VERSION "created by canmatrix"

NS_ :

BS_ :

BU_:

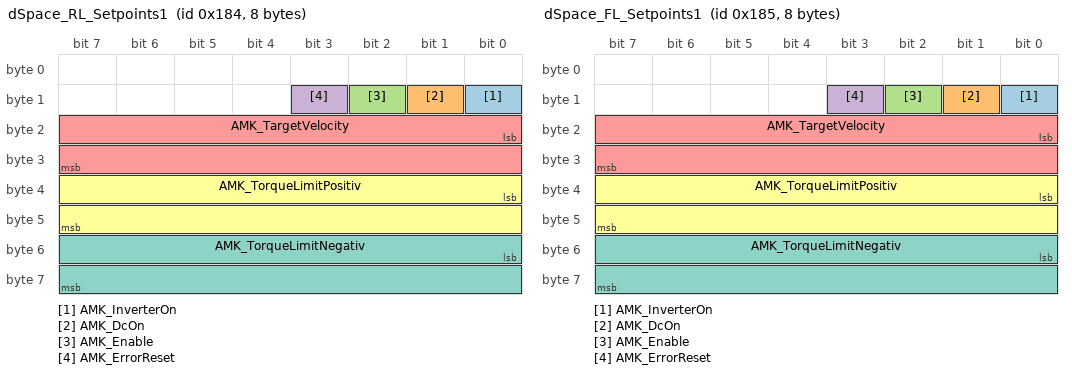
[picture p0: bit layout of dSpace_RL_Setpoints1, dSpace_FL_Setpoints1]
BO_ 388 dSpace_RL_Setpoints1: 8 Vector__XXX
  SG_ AMK_InverterOn : 8|1@1- (1,0) [0|1] "" Vector__XXX
  SG_ AMK_DcOn : 9|1@1- (1,0) [0|1] "" Vector__XXX
  SG_ AMK_Enable : 10|1@1- (1,0) [0|1] "" Vector__XXX
  SG_ AMK_ErrorReset : 11|1@1- (1,0) [0|1] "" Vector__XXX
  SG_ AMK_TargetVelocity : 16|16@1- (1,0) [-32768|32767] "" Vector__XXX
  SG_ AMK_TorqueLimitPositiv : 32|16@1- (1,0) [-32768|32767] "" Vector__XXX
  SG_ AMK_TorqueLimitNegativ : 48|16@1- (1,0) [-32768|32767] "" Vector__XXX

BO_ 389 dSpace_FL_Setpoints1: 8 Vector__XXX
  SG_ AMK_InverterOn : 8|1@1- (1,0) [0|1] "" Vector__XXX
  SG_ AMK_DcOn : 9|1@1- (1,0) [0|1] "" Vector__XXX
  SG_ AMK_Enable : 10|1@1- (1,0) [0|1] "" Vector__XXX
  SG_ AMK_ErrorReset : 11|1@1- (1,0) [0|1] "" Vector__XXX
  SG_ AMK_TargetVelocity : 16|16@1- (1,0) [-32768|32767] "" Vector__XXX
  SG_ AMK_TorqueLimitPositiv : 32|16@1- (1,0) [-32768|32767] "" Vector__XXX
  SG_ AMK_TorqueLimitNegativ : 48|16@1- (1,0) [-32768|32767] "" Vector__XXX

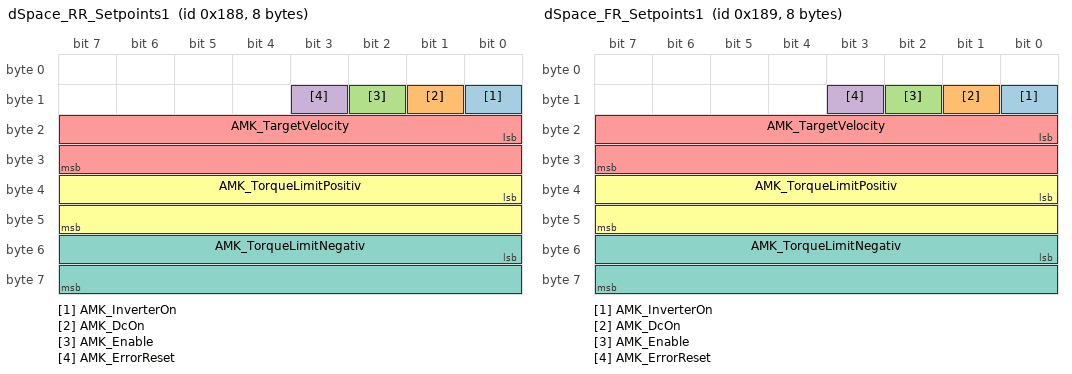
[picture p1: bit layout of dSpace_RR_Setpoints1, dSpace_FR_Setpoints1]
BO_ 392 dSpace_RR_Setpoints1: 8 Vector__XXX
  SG_ AMK_InverterOn : 8|1@1- (1,0) [0|1] "" Vector__XXX
  SG_ AMK_DcOn : 9|1@1- (1,0) [0|1] "" Vector__XXX
  SG_ AMK_Enable : 10|1@1- (1,0) [0|1] "" Vector__XXX
  SG_ AMK_ErrorReset : 11|1@1- (1,0) [0|1] "" Vector__XXX
  SG_ AMK_TargetVelocity : 16|16@1- (1,0) [-32768|32767] "" Vector__XXX
  SG_ AMK_TorqueLimitPositiv : 32|16@1- (1,0) [-32768|32767] "" Vector__XXX
  SG_ AMK_TorqueLimitNegativ : 48|16@1- (1,0) [-32768|32767] "" Vector__XXX

BO_ 393 dSpace_FR_Setpoints1: 8 Vector__XXX
  SG_ AMK_InverterOn : 8|1@1- (1,0) [0|1] "" Vector__XXX
  SG_ AMK_DcOn : 9|1@1- (1,0) [0|1] "" Vector__XXX
  SG_ AMK_Enable : 10|1@1- (1,0) [0|1] "" Vector__XXX
  SG_ AMK_ErrorReset : 11|1@1- (1,0) [0|1] "" Vector__XXX
  SG_ AMK_TargetVelocity : 16|16@1- (1,0) [-32768|32767] "" Vector__XXX
  SG_ AMK_TorqueLimitPositiv : 32|16@1- (1,0) [-32768|32767] "" Vector__XXX
  SG_ AMK_TorqueLimitNegativ : 48|16@1- (1,0) [-32768|32767] "" Vector__XXX

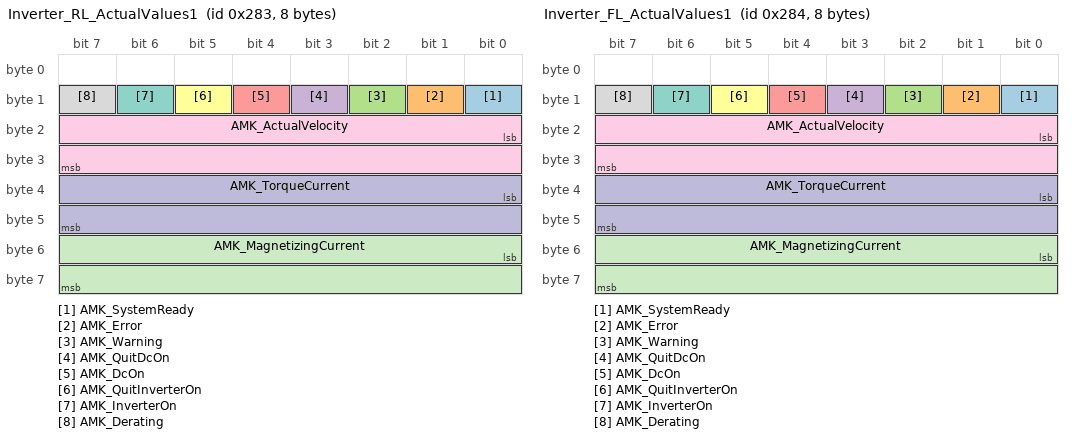
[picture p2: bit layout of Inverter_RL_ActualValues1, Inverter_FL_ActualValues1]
BO_ 643 Inverter_RL_ActualValues1: 8 Vector__XXX
  SG_ AMK_SystemReady : 8|1@1- (1,0) [0|1] "" Vector__XXX
  SG_ AMK_Error : 9|1@1- (1,0) [0|1] "" Vector__XXX
  SG_ AMK_Warning : 10|1@1- (1,0) [0|1] "" Vector__XXX
  SG_ AMK_QuitDcOn : 11|1@1- (1,0) [0|1] "" Vector__XXX
  SG_ AMK_DcOn : 12|1@1- (1,0) [0|1] "" Vector__XXX
  SG_ AMK_QuitInverterOn : 13|1@1- (1,0) [0|1] "" Vector__XXX
  SG_ AMK_InverterOn : 14|1@1- (1,0) [0|1] "" Vector__XXX
  SG_ AMK_Derating : 15|1@1- (1,0) [0|1] "" Vector__XXX
  SG_ AMK_ActualVelocity : 16|16@1- (1,0) [-32768|32767] "" Vector__XXX
  SG_ AMK_TorqueCurrent : 32|16@1- (1,0) [-32768|32767] "" Vector__XXX
  SG_ AMK_MagnetizingCurrent : 48|16@1- (1,0) [-32768|32767] "" Vector__XXX

BO_ 644 Inverter_FL_ActualValues1: 8 Vector__XXX
  SG_ AMK_SystemReady : 8|1@1- (1,0) [0|1] "" Vector__XXX
  SG_ AMK_Error : 9|1@1- (1,0) [0|1] "" Vector__XXX
  SG_ AMK_Warning : 10|1@1- (1,0) [0|1] "" Vector__XXX
  SG_ AMK_QuitDcOn : 11|1@1- (1,0) [0|1] "" Vector__XXX
  SG_ AMK_DcOn : 12|1@1- (1,0) [0|1] "" Vector__XXX
  SG_ AMK_QuitInverterOn : 13|1@1- (1,0) [0|1] "" Vector__XXX
  SG_ AMK_InverterOn : 14|1@1- (1,0) [0|1] "" Vector__XXX
  SG_ AMK_Derating : 15|1@1- (1,0) [0|1] "" Vector__XXX
  SG_ AMK_ActualVelocity : 16|16@1- (1,0) [-32768|32767] "" Vector__XXX
  SG_ AMK_TorqueCurrent : 32|16@1- (1,0) [-32768|32767] "" Vector__XXX
  SG_ AMK_MagnetizingCurrent : 48|16@1- (1,0) [-32768|32767] "" Vector__XXX

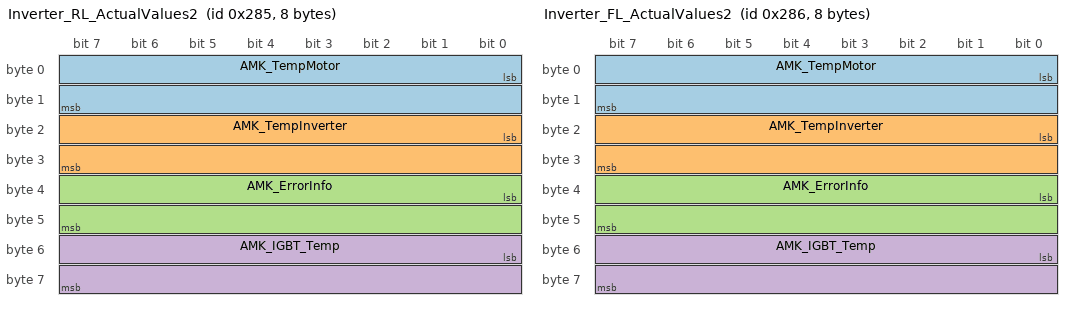
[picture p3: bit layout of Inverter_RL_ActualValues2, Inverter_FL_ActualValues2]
BO_ 645 Inverter_RL_ActualValues2: 8 Vector__XXX
  SG_ AMK_TempMotor : 0|16@1- (0.1,0) [-3276|3276] "�C" Vector__XXX
  SG_ AMK_TempInverter : 16|16@1- (0.1,0) [-3276|3276] "�C" Vector__XXX
  SG_ AMK_ErrorInfo : 32|16@1+ (1,0) [0|65535] "" Vector__XXX
  SG_ AMK_IGBT_Temp : 48|16@1- (0.1,0) [-3276|3276] "�C" Vector__XXX

BO_ 646 Inverter_FL_ActualValues2: 8 Vector__XXX
  SG_ AMK_TempMotor : 0|16@1- (0.1,0) [-3276|3276] "�C" Vector__XXX
  SG_ AMK_TempInverter : 16|16@1- (0.1,0) [-3276|3276] "�C" Vector__XXX
  SG_ AMK_ErrorInfo : 32|16@1+ (1,0) [0|65535] "" Vector__XXX
  SG_ AMK_IGBT_Temp : 48|16@1- (0.1,0) [-3276|3276] "�C" Vector__XXX

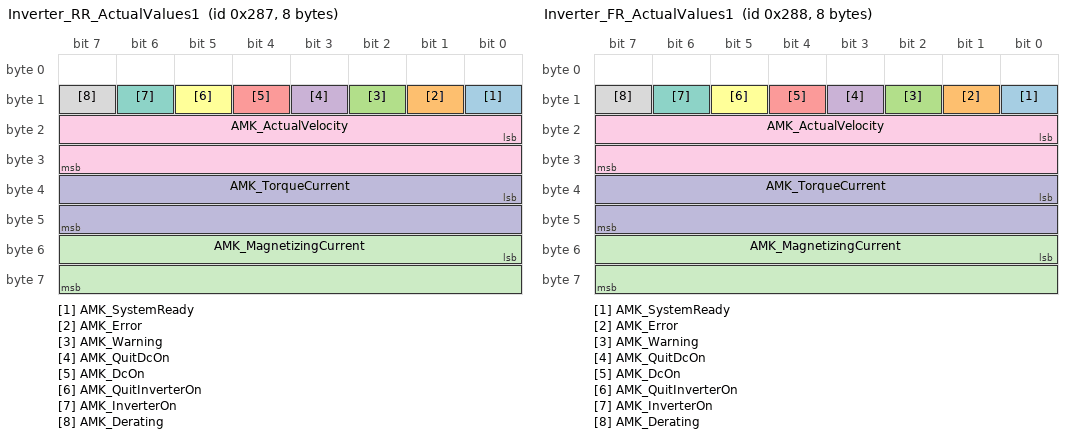
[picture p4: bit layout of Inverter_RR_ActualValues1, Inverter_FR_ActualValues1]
BO_ 647 Inverter_RR_ActualValues1: 8 Vector__XXX
  SG_ AMK_SystemReady : 8|1@1- (1,0) [0|1] "" Vector__XXX
  SG_ AMK_Error : 9|1@1- (1,0) [0|1] "" Vector__XXX
  SG_ AMK_Warning : 10|1@1- (1,0) [0|1] "" Vector__XXX
  SG_ AMK_QuitDcOn : 11|1@1- (1,0) [0|1] "" Vector__XXX
  SG_ AMK_DcOn : 12|1@1- (1,0) [0|1] "" Vector__XXX
  SG_ AMK_QuitInverterOn : 13|1@1- (1,0) [0|1] "" Vector__XXX
  SG_ AMK_InverterOn : 14|1@1- (1,0) [0|1] "" Vector__XXX
  SG_ AMK_Derating : 15|1@1- (1,0) [0|1] "" Vector__XXX
  SG_ AMK_ActualVelocity : 16|16@1- (1,0) [-32768|32767] "" Vector__XXX
  SG_ AMK_TorqueCurrent : 32|16@1- (1,0) [-32768|32767] "" Vector__XXX
  SG_ AMK_MagnetizingCurrent : 48|16@1- (1,0) [-32768|32767] "" Vector__XXX

BO_ 648 Inverter_FR_ActualValues1: 8 Vector__XXX
  SG_ AMK_SystemReady : 8|1@1- (1,0) [0|1] "" Vector__XXX
  SG_ AMK_Error : 9|1@1- (1,0) [0|1] "" Vector__XXX
  SG_ AMK_Warning : 10|1@1- (1,0) [0|1] "" Vector__XXX
  SG_ AMK_QuitDcOn : 11|1@1- (1,0) [0|1] "" Vector__XXX
  SG_ AMK_DcOn : 12|1@1- (1,0) [0|1] "" Vector__XXX
  SG_ AMK_QuitInverterOn : 13|1@1- (1,0) [0|1] "" Vector__XXX
  SG_ AMK_InverterOn : 14|1@1- (1,0) [0|1] "" Vector__XXX
  SG_ AMK_Derating : 15|1@1- (1,0) [0|1] "" Vector__XXX
  SG_ AMK_ActualVelocity : 16|16@1- (1,0) [-32768|32767] "" Vector__XXX
  SG_ AMK_TorqueCurrent : 32|16@1- (1,0) [-32768|32767] "" Vector__XXX
  SG_ AMK_MagnetizingCurrent : 48|16@1- (1,0) [-32768|32767] "" Vector__XXX

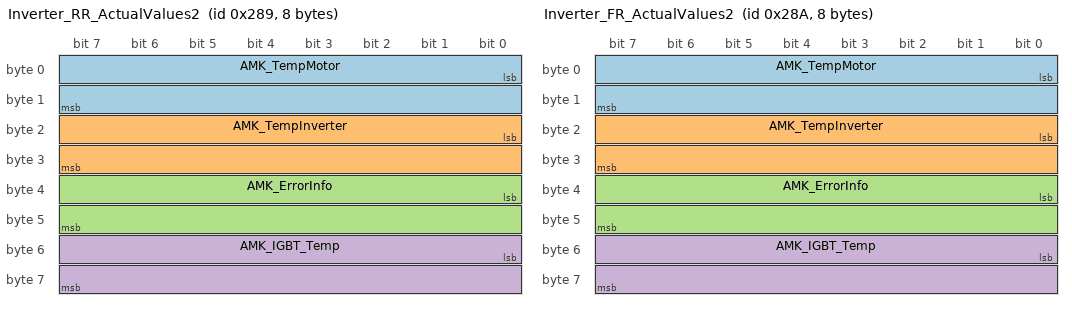
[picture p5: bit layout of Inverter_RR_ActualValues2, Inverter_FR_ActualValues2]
BO_ 649 Inverter_RR_ActualValues2: 8 Vector__XXX
  SG_ AMK_TempMotor : 0|16@1- (0.1,0) [-3276|3276] "�C" Vector__XXX
  SG_ AMK_TempInverter : 16|16@1- (0.1,0) [-3276|3276] "�C" Vector__XXX
  SG_ AMK_ErrorInfo : 32|16@1+ (1,0) [0|65535] "" Vector__XXX
  SG_ AMK_IGBT_Temp : 48|16@1- (0.1,0) [-3276|3276] "�C" Vector__XXX

BO_ 650 Inverter_FR_ActualValues2: 8 Vector__XXX
  SG_ AMK_TempMotor : 0|16@1- (0.1,0) [-3276|3276] "�C" Vector__XXX
  SG_ AMK_TempInverter : 16|16@1- (0.1,0) [-3276|3276] "�C" Vector__XXX
  SG_ AMK_ErrorInfo : 32|16@1+ (1,0) [0|65535] "" Vector__XXX
  SG_ AMK_IGBT_Temp : 48|16@1- (0.1,0) [-3276|3276] "�C" Vector__XXX

BA_DEF_ BO_ "GenMsgSendType" ENUM "NoMsgSendType","Cyclic","IfActive","CyclicIfActive","NotUsed";
BA_DEF_ SG_ "GenSigSendType" ENUM "NoSigSendType","Cyclic","OnWrite","OnWriteWithRepetition","OnChange","OnChangeWithRepetition","IfActive","IfActiveWithRepetition","NotUsed";
BA_DEF_DEF_ "GenMsgSendType" "NoMsgSendType";
BA_DEF_DEF_ "GenSigSendType" "NoSigSendType";
